# ATmega2561 device description
Architecture: AVR8; Family: megaAVR
Registers are 8-bit, access not given, no defined reset value unless marked. A register's access mark holds for its fields unless they carry their own. Offsets are from the block's base; [hi:lo] are bit positions; {n}, {i} and the like mark numbered series; 'fields as' and 'values as' point back to an identical list.

## TC1 (TC16 module) — Timer/Counter, 16-bit
Instances: TC1 0x00
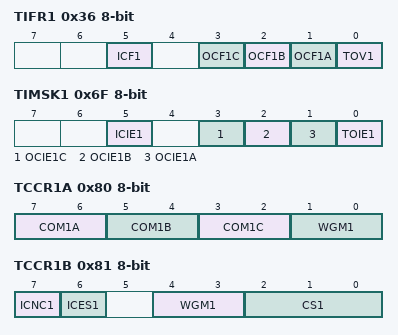
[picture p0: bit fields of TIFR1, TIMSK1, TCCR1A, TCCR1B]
0x36 TIFR1 — Timer/Counter1 Interrupt Flag register
  [5] ICF1 — Input Capture Flag 1
  [3] OCF1C — Output Compare Flag 1C
  [2] OCF1B — Output Compare Flag 1B
  [1] OCF1A — Output Compare Flag 1A
  [0] TOV1 — Timer/Counter1 Overflow Flag
0x6F TIMSK1 — Timer/Counter1 Interrupt Mask Register
  [5] ICIE1 — Timer/Counter1 Input Capture Interrupt Enable
  [3] OCIE1C — Timer/Counter1 Output Compare C Match Interrupt Enable
  [2] OCIE1B — Timer/Counter1 Output Compare B Match Interrupt Enable
  [1] OCIE1A — Timer/Counter1 Output Compare A Match Interrupt Enable
  [0] TOIE1 — Timer/Counter1 Overflow Interrupt Enable
0x80 TCCR1A — Timer/Counter1 Control Register A
  [7:6] COM1A — Compare Output Mode 1A, bits
  [5:4] COM1B — Compare Output Mode 1B, bits
  [3:2] COM1C — Compare Output Mode 1C, bits
  [1:0] WGM1 — Waveform Generation Mode
0x81 TCCR1B — Timer/Counter1 Control Register B
  [7] ICNC1 — Input Capture 1 Noise Canceler
  [6] ICES1 — Input Capture 1 Edge Select
  [4:3] WGM1 (bit 2 of the value upward) — Waveform Generation Mode
  [2:0] CS1 — Prescaler source of Timer/Counter 1
    0=No Clock Source (Stopped); 1=Running, No Prescaling; 2=Running, CLK/8; 3=Running, CLK/64; 4=Running, CLK/256; 5=Running, CLK/1024; 6=Running, ExtClk Tx Falling Edge; 7=Running, ExtClk Tx Rising Edge
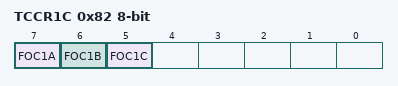
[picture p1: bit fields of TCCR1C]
0x82 TCCR1C — Timer/Counter 1 Control Register C
  [7] FOC1A — Force Output Compare 1A
  [6] FOC1B — Force Output Compare 1B
  [5] FOC1C — Force Output Compare 1C
0x84 TCNT1 16-bit — Timer/Counter1 Bytes
0x86 ICR1 16-bit — Timer/Counter1 Input Capture Register Bytes
0x88 OCR1A 16-bit — Timer/Counter1 Output Compare Register A Bytes
0x8A OCR1B 16-bit — Timer/Counter1 Output Compare Register B Bytes
0x8C OCR1C 16-bit — Timer/Counter1 Output Compare Register C Bytes

## JTAG — JTAG Interface
Instances: JTAG 0x00
0x51 OCDR — On-Chip Debug Related Register in I/O Memory
0x54 MCUSR — MCU Status Register
  [4] JTRF — JTAG Reset Flag
0x55 MCUCR — MCU Control Register
  [7] JTD — JTAG Interface Disable

## EXINT — External Interrupts
Instances: EXINT 0x00
0x3B PCIFR — Pin Change Interrupt Flag Register
  [2:0] PCIF — Pin Change Interrupt Flags
0x3C EIFR — External Interrupt Flag Register
  [7:0] INTF — External Interrupt Flags
0x3D EIMSK — External Interrupt Mask Register
  [7:0] INT — External Interrupt Request 7 Enable
0x68 PCICR — Pin Change Interrupt Control Register
  [2:0] PCIE — Pin Change Interrupt Enables
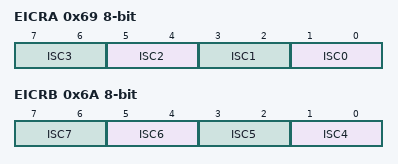
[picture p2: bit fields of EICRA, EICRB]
0x69 EICRA — External Interrupt Control Register A
  [all] fields
    0=Low Level of INTX; 1=Any Logical Change of INTX; 2=Falling Edge of INTX; 3=Rising Edge of INTX
  [2n+1:2n] ISC{n} (n=0..3) — External Interrupt Sense Control Bit
0x6A EICRB — External Interrupt Control Register B
  [all] fields
    values as the fields of EICRA
  [2n-7:2n-8] ISC{n} (n=4..7) — External Interrupt 7-4 Sense Control Bit
0x6B PCMSK0 — Pin Change Mask Register 0
  [7:0] PCINT — Pin Change Mask interrupt
0x6C PCMSK1 — Pin Change Mask Register 1
  [7:0] PCINT (bit 8 of the value upward) — Pin Change Mask interrupt
0x6D PCMSK2 — Pin Change Mask Register 2
  [7:0] PCINT (bit 16 of the value upward) — Pin Change Mask interrupt

## CPU — CPU Registers
Instances: CPU 0x00
Parameters: CORE_VERSION=V3
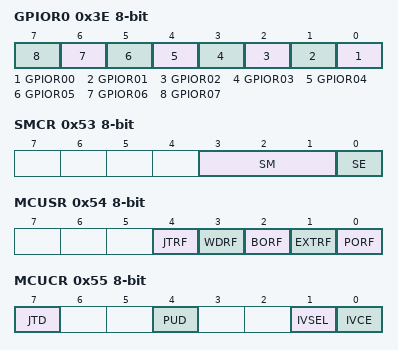
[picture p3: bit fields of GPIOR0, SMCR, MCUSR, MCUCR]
0x3E GPIOR0 — General Purpose IO Register 0
  [n] GPIOR{n:02} (n=0..7) — General Purpose IO Register 0 bit {n}
0x4A GPIOR1 — General Purpose IO Register 1
  [7:0] GPIOR (bit 10 of the value upward) — General Purpose IO Register 1 bis
0x4B GPIOR2 — General Purpose IO Register 2
  [7:0] GPIOR (bit 20 of the value upward) — General Purpose IO Register 2 bis
0x53 SMCR — Sleep Mode Control Register
  [3:1] SM — Sleep Mode Select bits
    0=IDLE; 1=ADC (ADC Noise Reduction (If Available)); 2=PDOWN (Power Down); 3=PSAVE (Power Save); 6=STDBY (Standby); 7=ESTDBY (Extended Standby)
  [0] SE — Sleep Enable
0x54 MCUSR — MCU Status Register
  [4] JTRF — JTAG Reset Flag
  [3] WDRF — Watchdog Reset Flag
  [2] BORF — Brown-out Reset Flag
  [1] EXTRF — External Reset Flag
  [0] PORF — Power-on reset flag
0x55 MCUCR — MCU Control Register
  [7] JTD — JTAG Interface Disable
  [4] PUD — Pull-up disable
  [1] IVSEL — Interrupt Vector Select
  [0] IVCE — Interrupt Vector Change Enable
0x5B RAMPZ bits used 1:0 — RAM Page Z Select Register
0x5C EIND bits used 0 — Extended Indirect Register
0x5D SP 16-bit — Stack Pointer
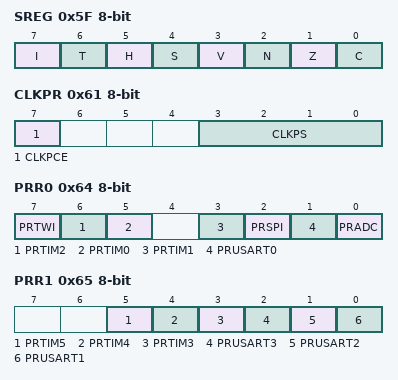
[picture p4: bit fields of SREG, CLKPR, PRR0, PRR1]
0x5F SREG — Status Register
  [7] I — Global Interrupt Enable
  [6] T — Bit Copy Storage
  [5] H — Half Carry Flag
  [4] S — Sign Bit
  [3] V — Two's Complement Overflow Flag
  [2] N — Negative Flag
  [1] Z — Zero Flag
  [0] C — Carry Flag
0x61 CLKPR
  [7] CLKPCE
  [3:0] CLKPS
    0=1; 1=2; 2=4; 3=8; 4=16; 5=32; 6=64; 7=128; 8=256
0x64 PRR0 — Power Reduction Register0
  [7] PRTWI — Power Reduction TWI
  [6] PRTIM2 — Power Reduction Timer/Counter2
  [5] PRTIM0 — Power Reduction Timer/Counter0
  [3] PRTIM1 — Power Reduction Timer/Counter1
  [2] PRSPI — Power Reduction Serial Peripheral Interface
  [1] PRUSART0 — Power Reduction USART0
  [0] PRADC — Power Reduction ADC
0x65 PRR1 — Power Reduction Register1
  [5] PRTIM5 — Power Reduction Timer/Counter5
  [4] PRTIM4 — Power Reduction Timer/Counter4
  [3] PRTIM3 — Power Reduction Timer/Counter3
  [2] PRUSART3 — Power Reduction USART3
  [1] PRUSART2 — Power Reduction USART2
  [0] PRUSART1 — Power Reduction USART1
0x66 OSCCAL — Oscillator Calibration Value
  [7:0] OSCCAL — Oscillator Calibration
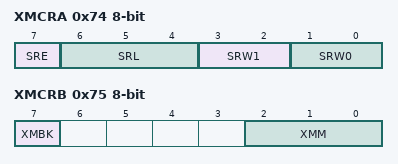
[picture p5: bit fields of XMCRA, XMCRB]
0x74 XMCRA — External Memory Control Register A
  [7] SRE — External SRAM Enable
  [6:4] SRL — Wait state page limit
    0=LS = N/A, US = 0x1100 - 0xFFFF; 1=LS = 0x2200 - 0x1FFF, US = 0x2000 - 0xFFFF; 2=LS = 0x2200 - 0x3FFF, US = 0x4000 - 0xFFFF; 3=LS = 0x2200 - 0x5FFF, US = 0x6000 - 0xFFFF; 4=LS = 0x2200 - 0x7FFF, US = 0x8000 - 0xFFFF; 5=LS = 0x2200 - 0x9FFF, US = 0xA000 - 0xFFFF; 6=LS = 0x2200 - 0xBFFF, US = 0xC000 - 0xFFFF; 7=LS = 0x2200 - 0xDFFF, US = 0xE000 - 0xFFFF
  [3:2] SRW1 — Wait state select bit upper page
    0=No wait-states; 1=Wait one cycle during read/write strobe; 2=Wait two cycles during read/write strobe; 3=Wait two cycles during read/write and wait one cycle before driving out new address
  [1:0] SRW0 — Wait state select bit lower page
    values as SRW1
0x75 XMCRB — External Memory Control Register B
  [7] XMBK — External Memory Bus Keeper Enable
  [2:0] XMM — External Memory High Mask
Value list OSCCAL_VALUE_ADDRESSES: 0=8_0_MHz
